# STM32L15xxE register map
File version: 1.0
CPU: 
Registers are 32-bit, read-write, reset 0x0 unless marked. A register's access mark holds for its fields unless they carry their own. Offsets are from the block's base; [hi:lo] are bit positions; {n}, {i} and the like mark numbered series.

## SYSCFG — System configuration controller
Base 0x40010000
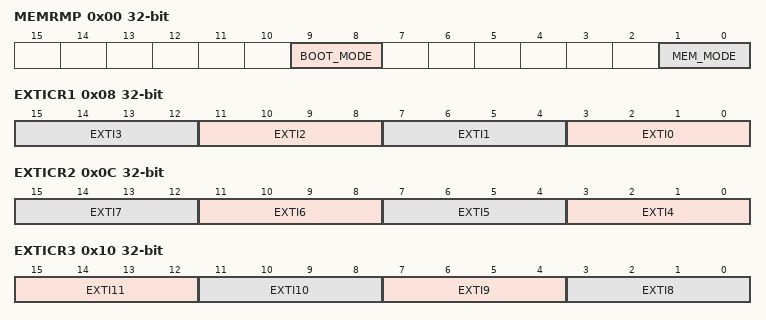
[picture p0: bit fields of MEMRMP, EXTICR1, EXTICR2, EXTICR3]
0x00 MEMRMP access per field — memory remap register
  [9:8] BOOT_MODE ro, [1:0] MEM_MODE rw
0x04 PMC — peripheral mode configuration register
  [0] USB_PU — USB pull-up
0x08 EXTICR1 — external interrupt configuration register 1
  [4n+3:4n] EXTI{n} (n=0..3) — EXTI x configuration (x = 0 to 3)
0x0C EXTICR2 — external interrupt configuration register 2
  [4n-13:4n-16] EXTI{n} (n=4..7) — EXTI x configuration (x = 4 to 7)
0x10 EXTICR3 — external interrupt configuration register 3
  [15:12] EXTI11 — EXTI x configuration (x = 8 to 11)
  [11:8] EXTI10
  [7:4] EXTI9 — EXTI x configuration (x = 8 to 11)
  [3:0] EXTI8 — EXTI x configuration (x = 8 to 11)
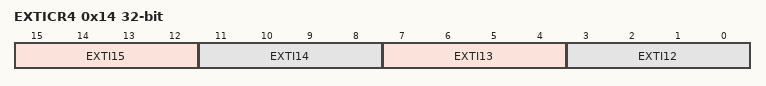
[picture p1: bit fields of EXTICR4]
0x14 EXTICR4 — external interrupt configuration register 4
  [15:12] EXTI15 — EXTI x configuration (x = 12 to 15)
  [11:8] EXTI14
  [7:4] EXTI13
  [3:0] EXTI12

## USB — Universal serial bus full-speed device interface
Base 0x40005C00
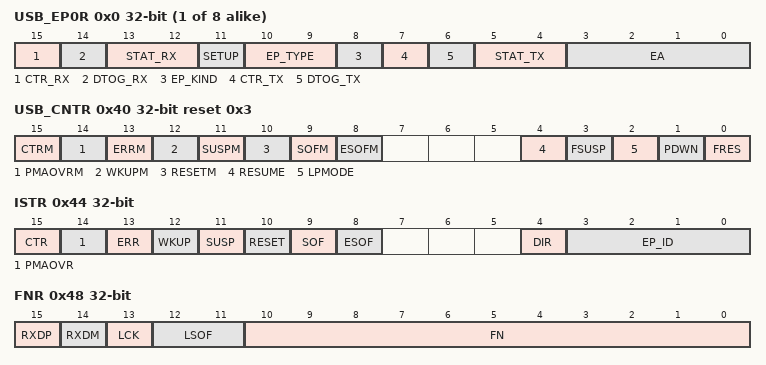
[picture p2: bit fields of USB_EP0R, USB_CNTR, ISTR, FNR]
{0x0+4i} USB_EP{i}R (i=0..7) — endpoint {i} register
  [15] CTR_RX — Correct transfer for reception
  [14] DTOG_RX — Data Toggle, for reception transfers
  [13:12] STAT_RX — Status bits, for reception transfers
  [11] SETUP — Setup transaction completed
  [10:9] EP_TYPE — Endpoint type
  [8] EP_KIND — Endpoint kind
  [7] CTR_TX — Correct Transfer for transmission
  [6] DTOG_TX — Data Toggle, for transmission transfers
  [5:4] STAT_TX — Status bits, for transmission transfers
  [3:0] EA — Endpoint address
0x40 USB_CNTR reset 0x3 — control register
  [15] CTRM — Correct transfer interrupt mask
  [14] PMAOVRM — Packet memory area over / underrun interrupt mask
  [13] ERRM — Error interrupt mask
  [12] WKUPM — Wakeup interrupt mask
  [11] SUSPM — Suspend mode interrupt mask
  [10] RESETM — USB reset interrupt mask
  [9] SOFM — Start of frame interrupt mask
  [8] ESOFM — Expected start of frame interrupt mask
  [4] RESUME — Resume request
  [3] FSUSP — Force suspend
  [2] LPMODE — Low-power mode
  [1] PDWN — Power down
  [0] FRES — Force USB Reset
0x44 ISTR — interrupt status register
  [15] CTR — Correct transfer
  [14] PMAOVR — Packet memory area over / underrun
  [13] ERR — Error
  [12] WKUP — Wakeup
  [11] SUSP — Suspend mode request
  [10] RESET — reset request
  [9] SOF — start of frame
  [8] ESOF — Expected start frame
  [4] DIR — Direction of transaction
  [3:0] EP_ID — Endpoint Identifier
0x48 FNR ro — frame number register
  [15] RXDP — Receive data + line status
  [14] RXDM — Receive data - line status
  [13] LCK — Locked
  [12:11] LSOF — Lost SOF
  [10:0] FN — Frame number
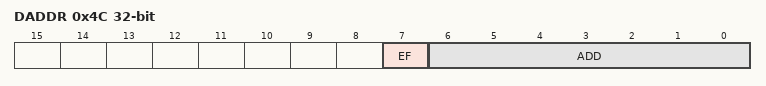
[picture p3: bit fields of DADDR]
0x4C DADDR — device address
  [7] EF — Enable function
  [6:0] ADD — Device address
0x50 BTABLE — Buffer table address
  [15:3] BTABLE — Buffer table

## USB_SRAM — Universal serial bus full-speed device interface
Base 0x40006000
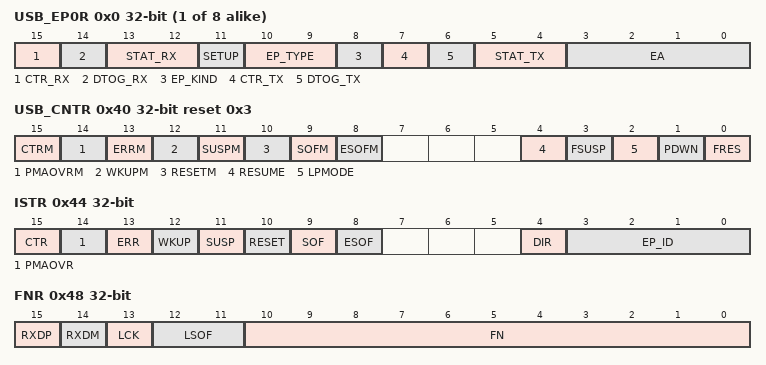
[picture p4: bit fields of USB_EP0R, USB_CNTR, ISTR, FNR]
{0x0+4i} USB_EP{i}R (i=0..7) — endpoint {i} register
  [15] CTR_RX — Correct transfer for reception
  [14] DTOG_RX — Data Toggle, for reception transfers
  [13:12] STAT_RX — Status bits, for reception transfers
  [11] SETUP — Setup transaction completed
  [10:9] EP_TYPE — Endpoint type
  [8] EP_KIND — Endpoint kind
  [7] CTR_TX — Correct Transfer for transmission
  [6] DTOG_TX — Data Toggle, for transmission transfers
  [5:4] STAT_TX — Status bits, for transmission transfers
  [3:0] EA — Endpoint address
0x40 USB_CNTR reset 0x3 — control register
  [15] CTRM — Correct transfer interrupt mask
  [14] PMAOVRM — Packet memory area over / underrun interrupt mask
  [13] ERRM — Error interrupt mask
  [12] WKUPM — Wakeup interrupt mask
  [11] SUSPM — Suspend mode interrupt mask
  [10] RESETM — USB reset interrupt mask
  [9] SOFM — Start of frame interrupt mask
  [8] ESOFM — Expected start of frame interrupt mask
  [4] RESUME — Resume request
  [3] FSUSP — Force suspend
  [2] LPMODE — Low-power mode
  [1] PDWN — Power down
  [0] FRES — Force USB Reset
0x44 ISTR — interrupt status register
  [15] CTR — Correct transfer
  [14] PMAOVR — Packet memory area over / underrun
  [13] ERR — Error
  [12] WKUP — Wakeup
  [11] SUSP — Suspend mode request
  [10] RESET — reset request
  [9] SOF — start of frame
  [8] ESOF — Expected start frame
  [4] DIR — Direction of transaction
  [3:0] EP_ID — Endpoint Identifier
0x48 FNR ro — frame number register
  [15] RXDP — Receive data + line status
  [14] RXDM — Receive data - line status
  [13] LCK — Locked
  [12:11] LSOF — Lost SOF
  [10:0] FN — Frame number
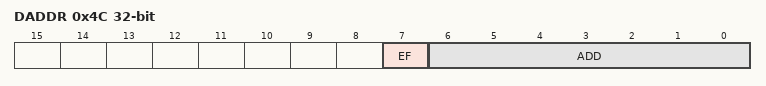
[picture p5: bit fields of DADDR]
0x4C DADDR — device address
  [7] EF — Enable function
  [6:0] ADD — Device address
0x50 BTABLE — Buffer table address
  [15:3] BTABLE — Buffer table

## USART3 — Universal synchronous asynchronous receiver transmitter
Base 0x40004800
Same registers: USART2 0x40004400, USART1 0x40013800
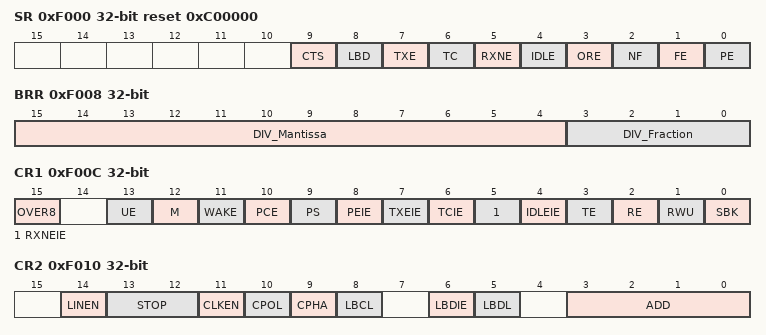
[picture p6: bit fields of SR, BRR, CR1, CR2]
0xF000 SR access per field reset 0xC00000 — Status register
  [9] CTS rw — CTS flag
  [8] LBD rw — LIN break detection flag
  [7] TXE ro — Transmit data register empty
  [6] TC rw — Transmission complete
  [5] RXNE rw — Read data register not empty
  [4] IDLE ro — IDLE line detected
  [3] ORE ro — Overrun error
  [2] NF ro — Noise detected flag
  [1] FE ro — Framing error
  [0] PE ro — Parity error
0xF004 DR — Data register
  [8:0] DR — Data value
0xF008 BRR — Baud rate register
  [15:4] DIV_Mantissa — mantissa of USARTDIV
  [3:0] DIV_Fraction — fraction of USARTDIV
0xF00C CR1 — Control register 1
  [15] OVER8 — Oversampling mode
  [13] UE — USART enable
  [12] M — Word length
  [11] WAKE — Wakeup method
  [10] PCE — Parity control enable
  [9] PS — Parity selection
  [8] PEIE — PE interrupt enable
  [7] TXEIE — TXE interrupt enable
  [6] TCIE — Transmission complete interrupt enable
  [5] RXNEIE — RXNE interrupt enable
  [4] IDLEIE — IDLE interrupt enable
  [3] TE — Transmitter enable
  [2] RE — Receiver enable
  [1] RWU — Receiver wakeup
  [0] SBK — Send break
0xF010 CR2 — Control register 2
  [14] LINEN — LIN mode enable
  [13:12] STOP — STOP bits
  [11] CLKEN — Clock enable
  [10] CPOL — Clock polarity
  [9] CPHA — Clock phase
  [8] LBCL — Last bit clock pulse
  [6] LBDIE — LIN break detection interrupt enable
  [5] LBDL — lin break detection length
  [3:0] ADD — Address of the USART node
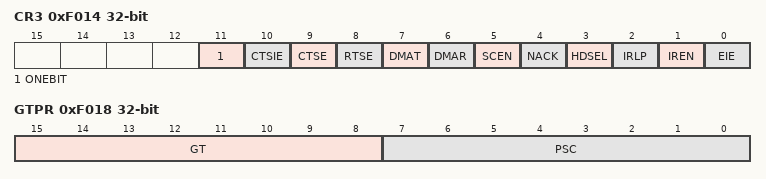
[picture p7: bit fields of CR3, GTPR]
0xF014 CR3 — Control register 3
  [11] ONEBIT — One sample bit method enable
  [10] CTSIE — CTS interrupt enable
  [9] CTSE — CTS enable
  [8] RTSE — RTS enable
  [7] DMAT — DMA enable transmitter
  [6] DMAR — DMA enable receiver
  [5] SCEN — Smartcard mode enable
  [4] NACK — Smartcard NACK enable
  [3] HDSEL — Half-duplex selection
  [2] IRLP — IrDA low-power
  [1] IREN — IrDA mode enable
  [0] EIE — Error interrupt enable
0xF018 GTPR — Guard time and prescaler register
  [15:8] GT — Guard time value
  [7:0] PSC — Prescaler value

## WWDG — Window watchdog
Base 0x40002C00
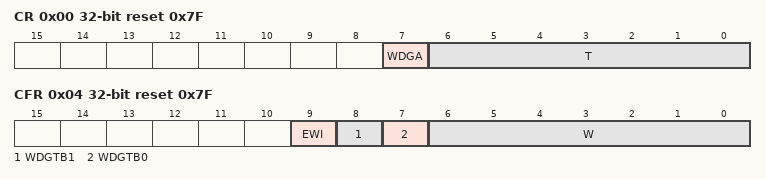
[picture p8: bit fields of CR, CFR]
0x00 CR access per field reset 0x7F — Control register
  [7] WDGA wo — Activation bit
  [6:0] T rw — 7-bit counter (MSB to LSB)
0x04 CFR access per field reset 0x7F — Configuration register
  [9] EWI wo — Early wakeup interrupt
  [8] WDGTB1 rw — Timer base
  [7] WDGTB0 rw
  [6:0] W rw — 7-bit window value
0x08 SR
  [0] EWIF
